# G32F031 register map
File version: 1.0
CPU: CM0PLUS r0p1, little endian, no MPU, no FPU, 2 interrupt priority bits
Registers are 32-bit, read-write, reset 0x0 unless marked. A register's access mark holds for its fields unless they carry their own. Offsets are from the block's base; [hi:lo] are bit positions; {n}, {i} and the like mark numbered series.

## SCU — System Control Unit
Base 0x40000400
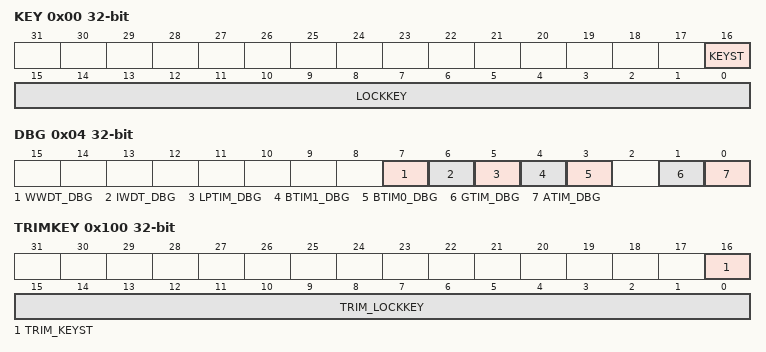
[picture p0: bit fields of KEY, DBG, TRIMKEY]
0x00 KEY access per field — Read-Write Protection Register
  [16] KEYST ro — Update disable
  [15:0] LOCKKEY wo — Counter enable
0x04 DBG — System DBG Control Register
  [7] WWDT_DBG — In DEBUG mode, WWDT counting method
  [6] IWDT_DBG — In DEBUG mode, IWDT counting method
  [5] LPTIM_DBG — In DEBUG mode, LPTIM counting method
  [4] BTIM1_DBG — In DEBUG mode, BTIM1 counting method
  [3] BTIM0_DBG — In DEBUG mode, BTIM0 counting method
  [1] GTIM_DBG — In DEBUG mode, GTIM counting method
  [0] ATIM_DBG — In DEBUG mode, ATIM counting method
0x100 TRIMKEY access per field — SCU Test Read/Write Protection Register
  [16] TRIM_KEYST ro — Test register read/write protection flag
  [15:0] TRIM_LOCKKEY wo — Password protection configuration for testing register read/write operations Write 0xa5a5 to unlock, while setting SCU_KEYST to 1 Write any other value to lock, while clearing SCU_KEYST to 0
0x130 VERSION ro
  [15:0] VERSION

## EINT — External interrupt/event controller
Base 0x40000800
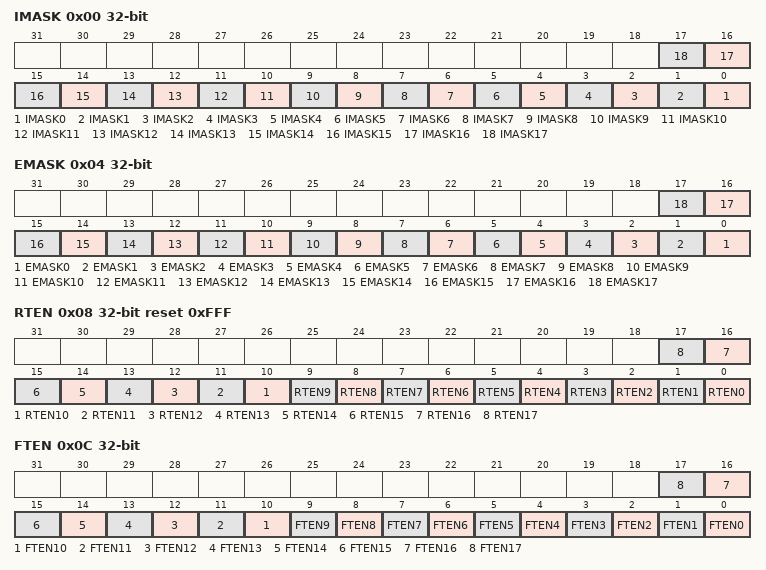
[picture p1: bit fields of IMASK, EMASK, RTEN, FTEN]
0x00 IMASK
  [n] IMASK{n} (n=0..17) — /
0x04 EMASK
  [n] EMASK{n} (n=0..17) — /
0x08 RTEN reset 0xFFF
  [n] RTEN{n} (n=0..17) — /
0x0C FTEN
  [n] FTEN{n} (n=0..17) — /
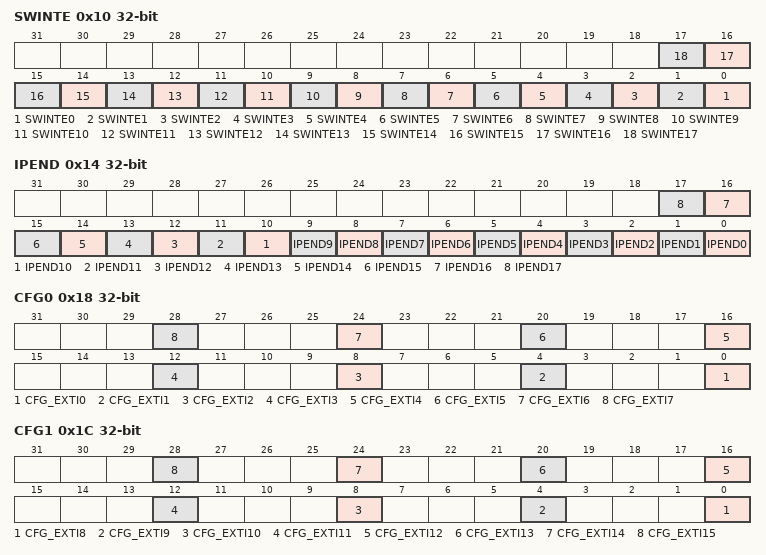
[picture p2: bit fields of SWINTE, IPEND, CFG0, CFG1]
0x10 SWINTE
  [n] SWINTE{n} (n=0..17) — /
0x14 IPEND
  [n] IPEND{n} (n=0..17) — /
0x18 CFG0
  [4n] CFG_EXTI{n} (n=0..7) — /
0x1C CFG1
  [4n-32] CFG_EXTI{n} (n=8..15) — /

## BTMR0 — Base timer
Base 0x40001800
Same registers: BTMR1 0x40001C00
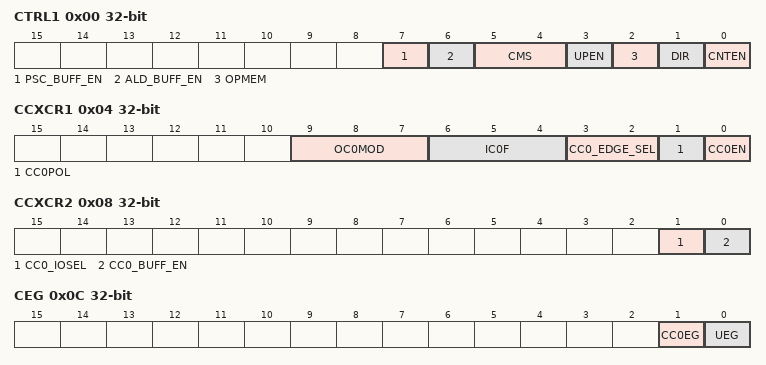
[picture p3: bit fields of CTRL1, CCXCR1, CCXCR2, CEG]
0x00 CTRL1 — control register 1
  [7] PSC_BUFF_EN — PSC preload enable
  [6] ALD_BUFF_EN — Auto-reload Preload Enable
  [5:4] CMS — Choose center alignment mode
  [3] UPEN — Update Disable
  [2] OPMEM — Single Pulse Mode Enable
  [1] DIR — Counter Direction
  [0] CNTEN — BTMR enable
0x04 CCXCR1 — channel control register 1
  [9:7] OC0MOD — Output Compare Channel0 Mode Configure
  [6:4] IC0F — Input filter coefficients (based on timer clock)
  [3:2] CC0_EDGE_SEL — When in input mode: capture the active edge
  [1] CC0POL — Capture/Compare Channel1 Output Polarity Configure
  [0] CC0EN — Capture/compare enable
0x08 CCXCR2 — channel control register 2
  [1] CC0_IOSEL — Channel 0 Input/Output Selection
  [0] CC0_BUFF_EN — CCR0 register auto-reload buffer enable
0x0C CEG wo — event generation register
  [1] CC0EG — Capture/compare 0 generation
  [0] UEG — Update generation
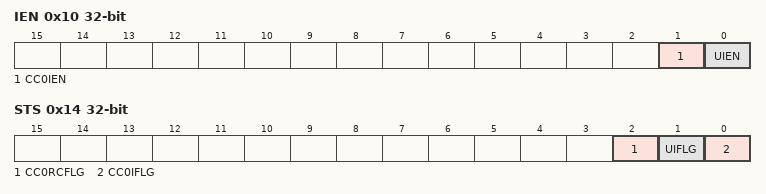
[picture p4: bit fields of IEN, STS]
0x10 IEN — interrupt enable register
  [1] CC0IEN — Capture/compare 0 interrupt enable
  [0] UIEN — Update interrupt enable
0x14 STS — status register
  [2] CC0RCFLG — Captuer/Compare Channel0 Repetition Capture Flag
  [1] UIFLG — Update interrupt flag
  [0] CC0IFLG — Capture/compare 0 interrupt flag
0x18 CNT — counter
  [15:0] CNT — Counter Value
0x1C PSC — prescaler
  [15:0] PSC — Prescaler value
0x20 AUTORLD reset 0xFFFF — auto-reload register
  [15:0] AUTORLD — Auto Reload Value
0x24 CC0 — capture/compare register 0
  [15:0] CC0 — Capture/Compare 0 value

## LPTMR — Low-power timer
Base 0x40002000
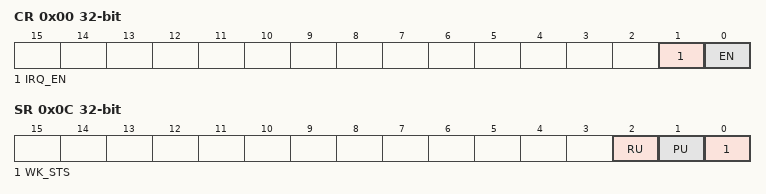
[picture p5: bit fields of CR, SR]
0x00 CR — Control register
  [1] IRQ_EN — Module interrupt enable
  [0] EN — Module enablement
0x04 PS — Prescaler register
  [15:0] PS — Prescaler divider
0x08 RV reset 0xFFFF — Reload register
  [15:0] RV — Awakening Value
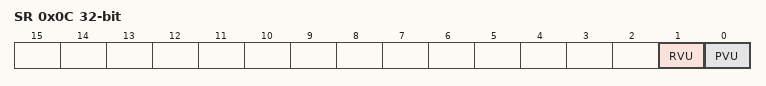
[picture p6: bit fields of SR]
0x0C SR ro — Status register
  [2] RU — Reload value update indication, automatically reset by hardware after update.
  [1] PU — PS value update indicator, hardware automatically resets after update.
  [0] WK_STS — Status Register, read SR register clear.
0x10 CNT ro — Counter register
  [15:0] CNT — Counter Value

## IWDT — Independent watchdog
Base 0x40002800
0x00 KEY wo
  [15:0] KEY — Key value (write only, read 0000h)
0x04 PR — Prescaler register
  [2:0] PS — Prescaler divider
0x08 RL reset 0xFFF — Reload register
  [11:0] RL — Watchdog counter reload value
0x0C SR ro — Status register
  [1] RVU — Watchdog prescaler value update
  [0] PVU — Watchdog counter reload value update
